# AE1C1F4051920PH0_CM55_HE_View register map
Vendor: Alif Semiconductor; Series: E1; File version: 1.0
CPU: CM55 r1p0, selectable endian, MPU, FPU, double-precision FPU, DSP, VTOR, 8 interrupt priority bits, 1 SAU regions
Registers are 32-bit, read-write, reset 0x0 unless marked. A register's access mark holds for its fields unless they carry their own. Offsets are from the block's base; [hi:lo] are bit positions; {n}, {i} and the like mark numbered series.

## LPUART
Base 0x43008000
Same registers: HCI_UART 0x4300A000, AHI_UART 0x4300B000, UART0 0x49018000, UART1 0x49019000, UART2 0x4901A000, UART3 0x4901B000, UART4 0x4901C000, UART5 0x4901D000
0x00 UART_RBR ro — Receive Buffer Register
  [8:0] RBR — Receive Buffer Register Field This field contains the data byte received on the serial input port. The data is valid only if the UART_LSR[DR] is set. If FIFOs are disabled (UART_FCR[FIFOE] set to 0), the data in the UART_RBR must be read before the next data arrives, otherwise it will be overwritten, resulting in an over-run error. If FIFOs are enabled (UART_FCR[FIFOE] set to 1), this register accesses the head of the Rx FIFO. If the Rx FIFO is full and this field is not read before the next data character arrives, then the data already in the FIFO will be preserved, but any incoming data will be lost and an over-run error occurs.
0x00 UART_DLL (alternate view of UART_RBR) — Divisor Latch Low Register
  [7:0] DLL — Divisor Latch Low Field The output baud rate is equal to serial clock frequency (SCLK for UART, PCLK for LPUART) divided by 16 times the value of the baud rate divisor, as follows: baud rate = (serial clock frequency) / (16 x divisor). Note: With the Divisor Latch registers (UART_DLL and UART_DLH) set to 0, the baud clock is disabled and no serial communication will occur. Also, once the DLL is set, at least 8 clock cycles of the slowest UART clock should be allowed to pass before transmitting or receiving data.
0x00 UART_THR (alternate view of UART_RBR) — Transmit Holding Register
  [8:0] THR wo — This field contains data to be transmitted on the serial output port. Data should only be written to the THR when the UART_LSR[THRE] is set. If FIFOs are disabled (UART_FCR[FIFOE] set to 0) and UART_LSR[THRE] is set, writing a single character to the THR field clears the UART_LSR[THRE]. Any additional writes to the THR before the UART_LSR[THRE] is set again cause the THR data to be overwritten. If FIFOs are enabled (UART_FCR[FIFOE] set to 1) and UART_LSR[THRE] is set, 32 number of characters of data may be written to the THR before the FIFO is full. Any attempt to write data when the FIFO is full results in the write data being lost. Note: The 9^th bit is applicable only when UART_LCR_EXT[TRANSMIT_MODE]=1.
0x04 UART_DLH — Divisor Latch High Register
  [7:0] DLH — Divisor Latch High The output baud rate is equal to serial clock frequency (SCLK for UART, PCLK for LPUART) divided by 16 times the value of the baud rate divisor, as follows: baud rate = (serial clock frequency) / (16 x divisor). Note: With the Divisor Latch registers (UART_DLL and UART_DLH) set to 0, the baud clock is disabled and no serial communication will occur. Also, once the DLH is set, at least 8 clock cycles of the slowest UART clock should be allowed to pass before transmitting or receiving data.
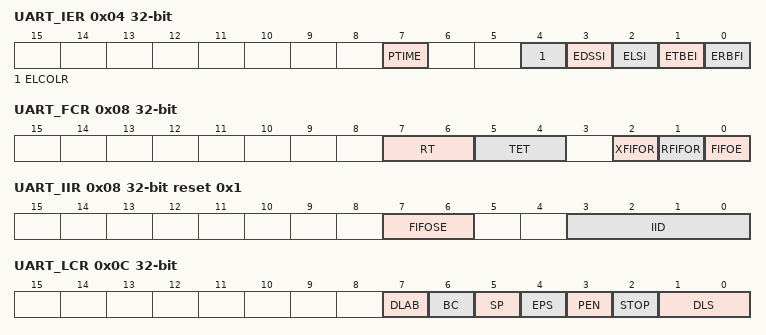
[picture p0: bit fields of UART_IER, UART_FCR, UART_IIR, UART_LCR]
0x04 UART_IER (alternate view of UART_DLH) — Interrupt Enable Register
  [7] PTIME — Programmable THRE Interrupt Mode Enable This bit is used to enable/disable the generation of THRE interrupt.
    0=Disable programmable THRE interrupt mode; 1=Enable programmable THRE interrupt mode
  [4] ELCOLR ro — This bit controls the method for clearing the status in the UART_LSR register. This is applicable only for overrun error, parity error, framing error, and break interrupt status bits of UART_LSR register.
    0=UART_LSR status bits are cleared either on reading Rx FIFO (UART_RBR) or UART_LSR register. The overrun error interrupt status is cleared only on reading UART_LSR register.
  [3] EDSSI — Enable Modem Status Interrupt This bit is used to enable/disable the generation of Modem Status interrupt. This is the fourth highest priority interrupt.
    0=Disable Modem Status interrupt; 1=Enable Modem Status interrupt
  [2] ELSI — Enable Receiver Line Status Interrupt This bit is used to enable/disable the generation of Receiver Line Status interrupt. This is the highest priority interrupt.
    0=Disable Receiver Line Status interrupt; 1=Enable Receiver Line Status interrupt
  [1] ETBEI — Enable Transmit Holding Register Empty Interrupt This bit is used to enable/disable the generation of THRE Interrupt. This is the third highest priority interrupt.
    0=Disable THRE interrupt; 1=Enable THRE interrupt
  [0] ERBFI — Enable Received Data Available Interrupt This bit is used to enable/disable the generation of Received Data Available interrupt and the Character Timeout interrupt (if FIFOs are enabled). These are the second highest priority interrupts.
    0=Disable Received Data Available interrupt; 1=Enable Received Data Available interrupt
0x08 UART_FCR — FIFO Control Register
  [7:6] RT wo — Rx Trigger This field is used to select the trigger level in the Rx FIFO at which the Received Data Available interrupt will be generated. In Auto Flow Control mode, it is used to determine when the RTS signal will be deasserted, but only when RTC flow-control trigger is disabled. It also determines when the DMA_RX_REQ signal will be asserted when in certain modes of operation. For details on DMA support, refer to Section UART DMA Requests.
    0=1 character in FIFO; 1=FIFO 1/4 full; 2=FIFO 1/2 full; 3=FIFO 2 characters till full
  [5:4] TET wo — Tx Empty Trigger This field is used to select the empty threshold level at which the THRE interrupts will be generated when the mode is active. It also determines when the DMA_TX_REQ signal will be asserted when in certain modes of operation. For details on DMA support, refer to Section UART DMA Requests.
    0=FIFO Empty; 1=2 characters in FIFO; 2=FIFO 1/4 full; 3=FIFO 1/2 full
  [2] XFIFOR wo — Tx FIFO Reset This bit resets the control portion of the Tx FIFO and treats the FIFO as empty. This will also deassert the DMA Tx request and single signals. Note that this bit is self-clearing.
    1=Tx FIFO reset
  [1] RFIFOR wo — Rx FIFO Reset This bit resets the control portion of the Rx FIFO and treats the FIFO as empty. This will also deassert the DMA Rx request and single signals. Note that this bit is self-clearing.
    1=Rx FIFO reset
  [0] FIFOE wo — FIFO Enable This bit enables/disables the Tx FIFOs and Rx FIFOs. Whenever the value of this bit is changed, both the Tx FIFO and Rx FIFO control portion of FIFOs are reset.
    0=FIFO disabled; 1=FIFO enabled
0x08 UART_IIR ro reset 0x1 (alternate view of UART_FCR) — Interrupt Identification Register
  [7:6] FIFOSE — FIFOs Enabled This field is used to indicate whether the FIFOs are enabled or disabled.
    0=FIFOs are disabled; 3=FIFOs are enabled
  [3:0] IID — Interrupt ID This field indicates the highest priority pending interrupt which can be one of the following types:
    0=Modem Status interrupt; 1=No interrupt pending; 2=THRE interrupt; 4=Received Data Available interrupt; 6=Receiver Line Status interrupt; 12=Character Timeout interrupt (can only occur when the FIFOs are enabled)
0x0C UART_LCR — Line Control Register
  [7] DLAB — Divisor Latch Access Bit This bit is used to enable reading and writing of the Divisor Latch registers (UART_DLL and UART_DLH). This bit must be cleared after initial baud rate setup in order to access other registers.
    0=Divisor Latch register is writable only when UART is not busy; 1=Divisor Latch register is always readable and writable
  [6] BC — Break Control Bit This bit is used to cause a break condition to be transmitted to the receiving device. If set to 1, the UART_TX is forced to the spacing (logic 0) state. When not in Loopback mode, as determined by UART_MCR[LOOPBACK], the UART_TX is forced low until the bit is cleared. When in Loopback mode, the break condition is internally looped back to the receiver.
    0=UART_TX is released for data transmission; 1=UART_TX is forced to spacing state
  [5] SP — Stick Parity This bit is used to force parity value. When PEN, EPS and SP bits are set to 1, the parity bit is transmitted and checked as logic 0. If PEN and SP are set to 1 and EPS is a logic 0, then parity bit is transmitted and checked as a logic 1.
    0=Stick parity disabled; 1=Stick parity enabled
  [4] EPS — Even Parity Select This bit is used to select between even and odd parity, when PEN set to 1.
    0=An odd parity is transmitted or checked; 1=An even parity is transmitted or checked
  [3] PEN — Parity Enable This bit is used to enable/disable parity generation and detection in transmitted and received serial character, respectively.
    0=Disable parity; 1=Enable parity
  [2] STOP — Number of Stop Bit This bit is used to select the number of stop bits per character that the peripheral will transmit and receive. If set to 0, one stop bit is transmitted in the serial data. If set to 1 and the data bits are set to 5 (UART_LCR[DLS] set to 0) one and a half stop bits are transmitted. Otherwise, 2 stop bits are transmitted. Note that regardless of the number of stop bits selected the receiver will only check the first stop bit. The STOP bit duration implemented by UART may appear longer due to IDLE time inserted between characters for some configurations and baud clock divisor values in the transmit direction; for details on IDLE time between transmitted transfers, refer to Section UART Back-to-Back Character Stream Transmission
    0=1 stop bit; 1=1.5 stop bits when UART_LCR[DLS] is 0, 2 stop bits otherwise
  [1:0] DLS — Data Length Select When UART_LCR_EXT[DLS_E] set to 0, this field is used to select the number of data bits per character that the peripheral will transmit and receive.
    {v}={v+5} data bits per character (v=0..3)
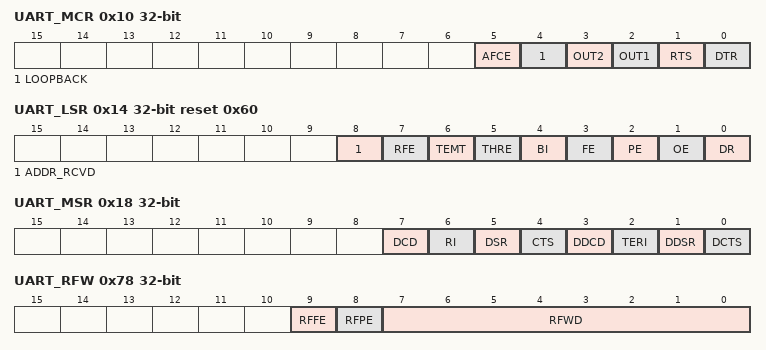
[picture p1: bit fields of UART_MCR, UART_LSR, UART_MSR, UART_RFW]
0x10 UART_MCR — Modem Control Register
  [5] AFCE — Auto Flow Control Enable When this bit is set and FIFOs are enabled, Auto Flow Control features are enabled.
    0=Auto Flow Control mode disabled; 1=Auto Flow Control mode enabled
  [4] LOOPBACK — Loopback Bit This bit is used to put the UART into a diagnostic mode for test purposes. Data on the UART_TX is held high, while UART_TX is looped back to the UART_RX, internally. In this mode all the interrupts are fully functional. In Loopback mode, the modem control inputs are disconnected and the modem control outputs are looped back to the inputs internally.
    0=Loopback mode disabled; 1=Loopback mode enabled
  [3] OUT2 — This bit is used to directly control the internal OUT2 signal. The value written to this location is inverted and driven out on OUT2. Note that in Loopback mode (UART_MCR[LOOPBACK] set to 1), the OUT2 signal is held inactive high while the value of this location is internally looped back to an input.
    0=OUT2 signal deasserted (logic 1); 1=OUT2 signal asserted (logic 0)
  [2] OUT1 — This bit is used to directly control the internal OUT1 signal. The value written to this location is inverted and driven out on OUT1. Note that in Loopback mode (UART_MCR[LOOPBACK] set to 1), the OUT1 signal is held inactive high while the value of this location is internally looped back to an input.
    0=OUT1 signal deasserted (logic 1); 1=OUT1 signal asserted (logic 0)
  [1] RTS — Request to Send This bit is used to directly control the UART_RTS output. The RTS bit is used to inform the modem that the UART is ready to exchange data. When Auto Flow Control mode is not enabled (UART_MCR[AFCE] set to 0), the UART_RTS is set low by programming UART_MCR[RTS] to high. When both Auto Flow Control mode and FIFOs are enabled (UART_MCR[AFCE] set to 1 and UART_FCR[FIFOE] set to 1, respectively), the UART_RTS is controlled in the same way, but is also gated with the Rx FIFO threshold trigger (UART_RTS is inactive high when above the threshold). The UART_RTS output will be deasserted when UART_MCR[RTS] is set to 0. Note that in Loopback mode (UART_MCR[LOOPBACK] set to 1), the UART_RTS output remains held inactive high, while the value of this bit is internally looped back to an input.
    0=UART_RTS deasserted (logic 1); 1=UART_RTS asserted (logic 0)
  [0] DTR — Data Terminal Ready This bit is used to directly control the DTR output. The value written to this bit is inverted and driven out on DTR. The DTR output is used to inform the modem that the UART is ready to establish communications. Note that in Loopback mode (UART_MCR[LOOPBACK] set to 1), the DTR output is held inactive high while the value of this bit is internally looped back to an input.
    0=DTR output deasserted (logic1); 1=DTR output asserted (logic 0)
0x14 UART_LSR ro reset 0x60 — Line Status Register
  [8] ADDR_RCVD — Address Received If 9-bit data mode is enabled (UART_LCR_EXT[DLS_E] set to 1), this bit is used to indicate the 9^th bit of the receive data is set to 1. This bit can also be used to indicate whether the incoming character is address or data. The 9^th bit, associated with a received character, is revealed when a character with the 9th bit set to 1 is at the top of the FIFO. Reading the UART_LSR clears the 9^th bit. Note: Read UART_LSR register before the next address byte arrives. If there is a delay in clearing the interrupt, then software will not be able to distinguish between multiple address related interrupts.
    0=Indicates the character is data; 1=Indicates the character is address
  [7] RFE — Rx FIFO Error This bit is only relevant when FIFOs are enabled (UART_FCR[FIFOE] set to 1). This bit is used to indicate if there is at least one parity error, framing error, or break interrupt in the FIFO. This bit is cleared when the UART_LSR is read and the character with the error is at the top of the Rx FIFO and there are no subsequent errors in the FIFO.
    0=No error in Rx FIFO; 1=Error in Rx FIFO
  [6] TEMT — Transmitter Empty If FIFOs are enabled (UART_FCR[FIFOE] set to 1), this bit is set whenever the internal transmit shift register and the Tx FIFO are both empty. If the FIFOs are disabled, this bit is set whenever the UART_THR and the transmit shift register are both empty.
    0=Transmitter not empty; 1=Transmitter empty
  [5] THRE — Transmit Holding Register Empty If THRE mode is disabled (UART_IER[PTIME] set to 0), regardless of whether FIFOs are enabled or not, this bit indicates that the UART_THR or Tx FIFO is empty. This bit is set whenever data is transferred from the UART_THR or Tx FIFO to the transmit shift register, and no new data has been written to the UART_THR or Tx FIFO. This also causes a THRE interrupt to occur, if the THRE interrupt is enabled. If both THRE Interrupt mode (UART_IER[PTIME] set to 1) and FIFOs (UART_FCR[FIFOE] set to 1) are enabled, the functionality is switched to indicate the Tx FIFO is full, and no longer controls THRE interrupts, which are then controlled by the UART_FCR[TET] threshold setting.
    0=THRE interrupt control is disabled; 1=THRE interrupt control is enabled
  [4] BI — Break Interrupt This bit is used to indicate the detection of a break sequence on the serial input data. This bit is set whenever the UART_RX is held in a logic 0 state for longer than the sum of start time + data bits + parity + stop bits. If the FIFOs are enabled, the character associated with the break condition is carried through the FIFO and is revealed when the character is at the top of the FIFO. Reading the UART_LSR or UART_RBR clears the BI bit. If FIFOs are disabled, this bit is set immediately and persists until the UART_LSR is read. Note: If a FIFO is full when a break condition is received, a FIFO overrun occurs. The break condition and all the information associated with it-parity and framing errors-is discarded; any information that a break character was received is lost.
    0=No break sequence detected; 1=Break sequence detected
  [3] FE — Framing Error This bit is used to indicate the occurrence of a framing error in the receiver. A framing error occurs when the receiver does not detect a valid STOP bit in the received data (see UART_LCR[STOP]). If the FIFOs are enabled, the framing error is associated with a character received, it is revealed when the character with the framing error is at the top of the FIFO. When a framing error occurs, the UART will attempt to resynchronize. It does this by assuming that the error was due to the start bit of the next character and then continues receiving the other bit (data, and/or parity, and stop). It should be noted that the UART_LSR[FE] bit will be set if a break interrupt has occurred, as indicated by the BI bit. This happens because the break character implicitly generates a framing error by holding the UART_RX to logic 0 for longer than the duration of a character. Reading the UART_LSR or UART_RBR clears this bit.
    0=No framing error; 1=Framing error
  [2] PE — Parity Error This bit is used to indicate the occurrence of a parity error in the receiver if the UART_LCR[PEN] bit is set. If the FIFOs are enabled, the parity error is associated with a character received, it is revealed when the character with the parity error arrives at the top of the FIFO. It should be noted that this bit will be set if a break interrupt has occurred, as indicated by the BI bit. In this situation, the PE bit is set if parity generation and detection is enabled (UART_LCR[PEN] is set to 1) and the parity is set to odd (UART_LCR[EPS] is set to 0). Reading the UART_LSR or UART_RBR clears this bit.
    0=No parity error; 1=Parity error
  [1] OE — Overrun Error This bit is used to indicate the occurrence of an overrun error. This occurs if a new data character was received before the previous data was read. If the FIFOs are enabled, an overrun error occurs when the FIFO is full and a new character arrives at the receiver. The data in the FIFO is retained and the data in the receive shift register is lost. Reading the UART_LSR or UART_RBR clears this bit.
    0=No overrun error; 1=Overrun error
  [0] DR — Data Ready This bit is used to indicate that the receiver contains at least one character in the UART_RBR or the receiver FIFO. This bit is cleared when the UART_RBR is read (if FIFOs are disabled) or when the receiver FIFO is empty (if FIFOs are enabled).
    0=No data ready; 1=Data ready
0x18 UART_MSR ro — Modem Status Register
  [7] DCD — Data Carrier Detect This bit is used to indicate the current state of the modem control line DCD. When the Data Carrier Detect input (DCD) is asserted, it indicates that the carrier has been detected by the modem or data set. In Loopback mode (UART_MCR[LOOPBACK] set to 1), DCD is the same as UART_MCR[OUT2] bit.
    0=DCD input is deasserted (logic 1); 1=DCD input is asserted (logic 0)
  [6] RI — Ring Indicator This bit is used to indicate the current state of the modem control line RI. When this bit is asserted, it indicates that a telephone ringing signal has been received by the modem data set. In Loopback mode (UART_MCR[LOOPBACK] set to 1), RI is the same as UART_MCR[OUT1].
    0=RI input is deasserted (logic 1); 1=RI input is asserted (logic 0)
  [5] DSR — Data Set Ready This bit is used to indicate the current state of the modem control line DSR. When this bit is asserted, it indicates that the modem or data set is ready to establish communications with the UART. In Loopback mode (UART_MCR[LOOPBACK] set to 1), DSR is the same as UART_MCR[DTR].
    0=DSR input is deasserted (logic 1); 1=DSR input is asserted (logic 0)
  [4] CTS — Clear to Send This bit is used to indicate the current state of the modem control line CTS. When this bit is asserted, it indicates that the modem or data set is ready to exchange data with the UART. In Loopback mode (UART_MCR[LOOPBACK] set to 1), CTS is the same as UART_MCR[RTS].
    0=CTS input is deasserted (logic 1); 1=CTS input is asserted (logic 0)
  [3] DDCD — Delta Data Carrier Detect This bit is used to indicate that the modem control line DCD has changed since the last time the UART_MSR was read. Reading the UART_MSR clears the DDCD bit. In Loopback mode (UART_MCR[LOOPBACK] set to 1), DDCD reflects changes on UART_MCR[OUT2]. Note: If the DDCD bit is not set and the DCD signal is asserted (low) and a reset occurs, then the DDCD bit will get set when the reset is removed, provided that the DCD signal remains asserted.
    0=No change on DCD since last read of UART_MSR; 1=Change on DCD since last read of UART_MSR
  [2] TERI — Trailing Edge of Ring Indicator This bit is used to indicate that a change on the input RI (from an active low, to an inactive high state) has occurred since the last time the UART_MSR was read. Reading the UART_MSR clears the TERI bit. In Loopback mode (UART_MCR[LOOPBACK] set to 1), this bit reflects a change in state from high to low for UART_MCR[OUT1].
    0=No change on RI since last read of UART_MSR; 1=Change on RI since last read of UART_MSR
  [1] DDSR — Delta Data Set Ready This bit is used to indicate that the modem control line DSR has changed since the last time the UART_MSR was read. Reading the UART_MSR clears the DDSR bit. In Loopback mode (UART_MCR[LOOPBACK] set to 1), DDSR reflects changes on UART_MCR[DTR]. Note: If the DDSR bit is not set and the DSR signal is asserted (low) and a reset occurs, then the DDSR bit will be set when the reset is removed if the DSR signal remains asserted.
    0=No change on DSR since last read of UART_MSR; 1=Change on DSR since last read of UART_MSR
  [0] DCTS — Delta Clear to Send This bit is used to indicate that the modem control line CTS has changed since the last time the UART_MSR was read. Reading the UART_MSR clears the DCTS bit. In Loopback mode (UART_MCR[LOOPBACK] set to 1), DCTS reflects changes on UART_MCR[RTS]. Note: If the DCTS bit is not set and the CTS signal is asserted (low) and a reset occurs, then the DCTS bit will be set when the reset is removed if the CTS signal remains asserted.
    0=No change on CTS since last read of UART_MSR; 1=Change on CTS since last read of UART_MSR
0x1C UART_SCR — Scratchpad Register
  [7:0] SCR — This field is used as a temporary storage space. It has no defined purpose in the UART.
{0x30+4i} UART_SRBR[{i}] (i=0..15) ro — Shadow Receive Buffer Register (n)
  [8:0] SRBRN — This is a shadow field for the UART_RBR[RBR] field and has been allocated sixteen 32-bit locations to accommodate burst accesses from the master. This field contains the data byte received on the UART_RX. The data in this field is valid only if the UART_LSR[DR] bit is set. If FIFOs are disabled (UART_FCR[FIFOE] set to 0), the data in the UART_RBR[RBR] must be read before the next data arrives, otherwise it will be overwritten, resulting in an overrun error. If FIFOs are enabled (UART_FCR[FIFOE] set to 1), this register accesses the head of the Rx FIFO. If the Rx FIFO is full and this field is not read before the next data character arrives, then the data already in the FIFO will be preserved, but any incoming data will be lost. An overrun error will also occur.
{0x30+4i} UART_STHR[{i}] (i=0..15) (alternate view of UART_SRBR[{i}]) — Shadow Transmit Holding Register (n)
  [8:0] STHRN wo — This is a shadow field for the UART_THR[THR] and has been allocated sixteen 32-bit locations to accommodate burst accesses from the master. This field contains data to be transmitted on the UART_TX. Data should only be written to the UART_THR when the UART_LSR[THRE] bit is set. If FIFOs are disabled (UART_FCR[FIFOE] set to 0) and UART_LSR[THRE] is set, writing a single character to the UART_THR[THR] clears the UART_LSR[THRE]. Any additional writes to the UART_THR[THR] before the UART_LSR[THRE] is set again causes the UART_THR[THR] data to be overwritten. If FIFOs are enabled (UART_FCR[FIFOE] set to 1) and UART_LSR[THRE] is set, 32 data characters may be written to the UART_THR[THR] before the FIFO is full. Any attempt to write data when the FIFO is full results in the write data being lost.
0x70 UART_FAR — FIFO Access Register
  [0] FAR — This bit is used to enable a FIFO access mode for testing, so that the Rx FIFO can be written and the Tx FIFO can be read by the master when FIFOs are enabled. When FIFOs are not enabled, it allows the UART_RBR[RBR] to be written by the master and the UART_THR[THR] to be read by the master. Note: When the FIFO access mode is enabled/disabled, the control portion of the Rx FIFO and Tx FIFO is reset and the FIFOs are treated as empty.
    0=FIFO access mode disabled; 1=FIFO access mode enabled
0x74 UART_TFR ro — Tx FIFO Read Register
  [7:0] TFR — This field is only valid when FIFO access mode is enabled (UART_FAR[FAR] set to 1). When FIFOs are enabled, reading this field gives the data at the top of the Tx FIFO. Each consecutive read pops the Tx FIFO and gives the next data value that is currently at the top of the FIFO. When FIFOs are not enabled, reading this field gives the data in the UART_THR[THR] field.
0x78 UART_RFW — Rx FIFO Write Register
  [9] RFFE wo — Rx FIFO Framing Error When FIFOs are enabled, this bit is used to write framing error detection information to the Rx FIFO. When FIFOs are not enabled, this bit is used to write framing error detection information to the UART_RBR[RBR].
    0=Frame error disabled; 1=Frame error enabled
  [8] RFPE wo — Rx FIFO Parity Error When FIFOs are enabled, this bit is used to write parity error detection information to the Rx FIFO. When FIFOs are not enabled, this bit is used to write parity error detection information to the UART_RBR[RBR].
    0=Parity error disabled; 1=Parity error enabled
  [7:0] RFWD wo — Rx FIFO Write Data When FIFOs are enabled, the data that is written to this field is pushed into the Rx FIFO. Each consecutive write pushes the new data to the next write location in the Rx FIFO. When FIFOs are not enabled, the data that is written to this field is pushed into the UART_RBR[RBR].
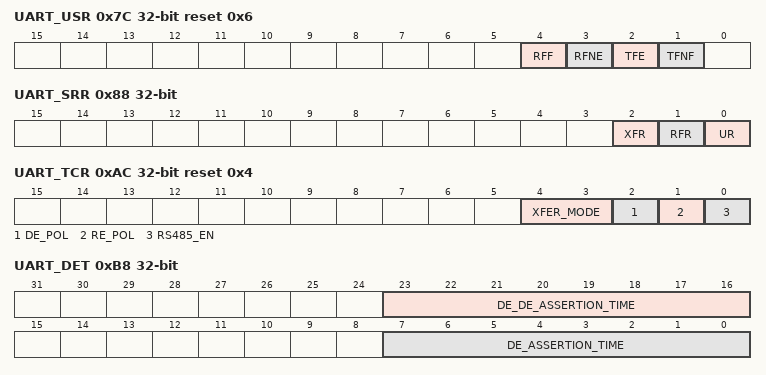
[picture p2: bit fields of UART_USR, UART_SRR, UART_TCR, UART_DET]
0x7C UART_USR ro reset 0x6 — UART Status Register
  [4] RFF — Rx FIFO Full This bit is used to indicate that the Rx FIFO is completely full. This bit is cleared when the Rx FIFO is no longer full.
    0=Rx FIFO is not full; 1=Rx FIFO is full
  [3] RFNE — Rx FIFO Not Empty This bit is used to indicate that the Rx FIFO contains one or more entries. This bit is cleared when the Rx FIFO is empty.
    0=Rx FIFO is empty; 1=Rx FIFO is not empty
  [2] TFE — Tx FIFO Empty This bit is used to indicate that the Tx FIFO is completely empty. This bit is cleared when the Tx FIFO is no longer empty.
    0=Tx FIFO is not empty; 1=Tx FIFO is empty
  [1] TFNF — Tx FIFO Not Full This bit is used to indicate that the Tx FIFO is not full. This bit is cleared when the Tx FIFO is full.
    0=Tx FIFO is full; 1=Tx FIFO is not full
0x80 UART_TFL ro — Tx FIFO Level Register
  [5:0] TFL — Transmit FIFO Level This field indicates the number of data entries in the Tx FIFO.
0x84 UART_RFL ro — Rx FIFO Level Register
  [5:0] RFL — Receive FIFO Level This field indicates the number of data entries in the Rx FIFO.
0x88 UART_SRR — Software Reset Register
  [2] XFR wo — Tx FIFO Reset This is a shadow bit for the UART_FCR[XFIFOR] bit. It is used to remove the burden on software of having to store previously written UART_FCR values just to reset the Tx FIFO. This resets the control portion of the Tx FIFO and treats the FIFO as empty. This will also deassert the DMA Tx request and single signals. Note that this bit is self-clearing.
  [1] RFR wo — Rx FIFO Reset This is a shadow bit for the UART_FCR[RFIFOR] bit. It is used to remove the burden on software of having to store previously written UART_FCR values just to reset the Rx FIFO. This resets the control portion of the Rx FIFO and treats the FIFO as empty. This will also deassert the DMA Rx request and single signals. Note that this bit is self-clearing.
  [0] UR wo — UART Reset This bit asynchronously resets the UART and synchronously removes the reset assertion. Both PCLK and SCLK (UART only) will be reset.
    0=No UART reset; 1=UART reset
0x8C UART_SRTS — Shadow Request to Send Register
  [0] SRTS — This is a shadow bit for the UART_MCR[RTS] bit, used to remove the burden of having to perform a read / modify write on the UART_MCR. This is used to directly control the UART_RTS output. The UART_RTS is used to inform the modem or data set that the UART is ready to exchange data. When UART_MCR[AFCE] bit is set to 0, the UART_RTS output is set low by programming UART_MCR[RTS] to a high. When UART_MCR[AFCE] bit is set to 1 and UART_FCR[FIFOE] set to 1, the UART_RTS signal is controlled in the same way, but is also gated with the Rx FIFO threshold trigger (UART_RTS signal is in active high when above the threshold) only when RTC flow-control trigger is disabled; otherwise it is gated by the Rx FIFO almost-full trigger, where almost full refers to two available slots in the FIFO (UART_RTS signal is in active high when above the threshold). Note: In Loopback mode (UART_MCR[LOOPBACK] bit set to 1), the UART_RTS signal is held in active high while the value of this bit is internally looped back to an input.
    0=Shadow UART_RTS logic 1; 1=Shadow UART_RTS logic 0
0x90 UART_SBCR — Shadow Break Control Register
  [0] SBCB — This is a shadow bit for the UART_LCR[BC] bit, used to remove the burden of having to perform a read / modify write on the UART_LCR. It is used to cause a break condition to be transmitted to the receiving device. If SBCB is set to 1 the UART_TX signal is forced to the spacing (logic 0) state. When not in Loopback mode (UART_MCR[LOOPBACK] set to 0), the UART_TX signal is forced low until the UART_LCR[BC] bit is cleared.
    0=No spacing on UART_TX signal; 1=UART_TX forced to the spacing
0x98 UART_SFE — Shadow FIFO Enable Register
  [0] SFE — This is a shadow bit for the UART_FCR[FIFOE] bit. It is used to remove the burden of having to store the previously written value to the UART_FCR in memory and and masking it, so that only the UART_FCR[FIFOE] bit gets updated. This enables/disables the Tx and Rx FIFOs. If this bit is set to 0 after being enabled then both the Tx and Rx control portion of FIFOs will be reset.
    0=FIFOs are disabled; 1=FIFOs are enabled
0x9C UART_SRT — Shadow RCVR Trigger Register
  [1:0] SRT — This is a shadow field for the UART_FCR[RT] field. It is used to remove the burden of having to store the previously written value to the UART_FCR[RT] in memory and and masking it, so that only the UART_FCR[RT] bit gets updated. SRT is used to select the trigger level in the Rx FIFO at which the Received Data Available interrupt will be generated.
    0=1 character in FIFO; 1=FIFO 1/4 full; 2=FIFO 1/2 full; 3=FIFO 2 less than full
0xA0 UART_STET — Shadow Tx Empty Trigger Register
  [1:0] STET — This is a shadow field for the UART_FCR[TET] field. It is used to remove the burden of having to store the previously written value to the UART_FCR[TET] in memory and and masking it, so that only the UART_FCR[TET] bit gets updated. STET is used to select the empty threshold level at which the THRE interrupts will be generated when the mode is active.
    0=FIFO empty; 1=2 characters in FIFO; 2=FIFO 1/4 full; 3=FIFO 1/2 full
0xA4 UART_HTX — Halt Tx Register
  [0] HTX — This bit is used to halt transmissions for testing, so that the Tx FIFO is filled by the master when FIFOs are enabled. Note: If FIFOs are not enabled the setting of this bit will have no effect on operation.
    0=Halt transmission disabled; 1=Halt transmission enabled
0xA8 UART_DMASA — DMA Software Acknowledge Register
  [0] DMASA wo — This bit is used to perform DMA software acknowledge if a transfer needs to be terminated due to an error condition. For example, if the DMA disables the channel, then the UART should clear its request. This will cause the Tx request, Tx single, Rx request and Rx single signals to deassert. Note: This bit is self-clearing.
    1=DMA software acknowledge
0xAC UART_TCR reset 0x4 — Transceiver Control Register
  [4:3] XFER_MODE — Transfer Mode Hardware will consider the Turnaround timings programmed in the UART_TAT register while switching from RE to DE, or DE to RE. For transmission hardware will wait if it is in middle of receiving any transfer, before it starts transmitting. Once the Tx FIFO becomes empty, RE signal gets enabled and DE signal will be disabled. Hardware will consider the Turnaround timings which are programmed in the UART_TAT register while switching from RE to DE or DE to RE. The DE and RE signals are strictly complementary to each other.
    0=In this mode, transmit and receive can happen simultaneously. UART_DE_EN[DE_ENABLE], UART_RE_EN[RE_ENABLE] can be enabled at any point of time. Turnaround timing as programmed in the UART_TAT register is not applicable in this mode.; 1=In this mode, DE and RE are mutually exclusive. Either DE or RE is expected to be enabled.; 2=In this mode, DE and RE are mutually exclusive. Once UART_DE_EN/UART_RE_EN register is set-by default RE will be enabled and UART controller will be ready to receive. If the SW programs the Tx FIFO with the data, then UART (after ensuring no receive is in progress), disables RE and enables DE signal.
  [2] DE_POL — Driver Enable Polarity
    0=DE signal is active low; 1=DE signal is active high
  [1] RE_POL — Receiver Enable Polarity NOTE: The reset value for UART is 0x0, and for LPUART it is 0x1.
    0=RE signal is active low; 1=RE signal is active high
  [0] RS485_EN — RS485 Transfer Enable
    1=The transfers will happen in RS485 mode. All other fields of this register are applicable.
0xB0 UART_DE_EN — Driver Output Enable Register
  [0] DE_ENABLE — This bit is used to control assertion and deassertion of DE signal.
    0=Deassert DE signal; 1=Assert DE signal
0xB4 UART_RE_EN — Receiver Output Enable Register
  [0] RE_ENABLE — This bit is used to control assertion and deassertion of RE signal.
    0=Deassert RE signal; 1=Assert RE signal
0xB8 UART_DET — Driver Output Enable Timing Register
  [23:16] DE_DE_ASSERTION_TIME — Driver Enable Deassertion Time This field controls the amount of time (in terms of number of SCLK periods) between the end of the stop bit on the UART_TX signal to the falling edge of DE signal.
  [7:0] DE_ASSERTION_TIME — Driver Enable Assertion Time This field controls the amount of time (in terms of number of SCLK periods) between the assertion of rising edge of DE signal to serial transmit enable. Any data in transmit buffer, will start on UART_TX signal after the transmit enable.
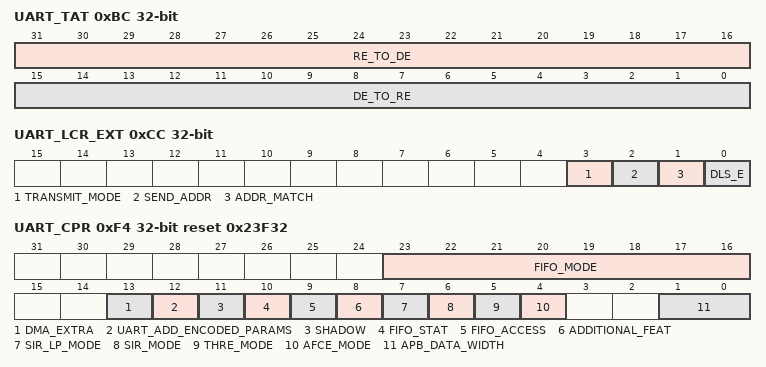
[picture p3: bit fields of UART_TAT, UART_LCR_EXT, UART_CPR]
0xBC UART_TAT — Turnaround Timing Register
  [31:16] RE_TO_DE — Receiver Enable to Driver Enable Turnaround time Turnaround time (in terms of SCLK) for RE deassertion to DE assertion: - If the UART_DET[DE_ASSERTION_TIME] field is 0, then the actual value is the programmed value + 3. - If the UART_DET[DE_ASSERTION_TIME] field is 1, then the actual value is the programmed value + 2. - If the UART_DET[DE_ASSERTION_TIME] field is greater than 1, then the actual value is the programmed value + 1.
  [15:0] DE_TO_RE — Driver Enable to Receiver Enable TurnAround time. Turnaround time (in terms of SCLK) for DE Deassertion to RE assertion: The actual time is the programmed value + 1.
0xC0 UART_DLF — Divisor Latch Fraction Register
  [3:0] DLF — This field defines the fractional value that is added to the integer value set by UART_DLH, UART_DLL. Fractional value = DLF / 2^DLF_SIZE, where DLF_SIZE = 4. For more information, see Section UART Fractional Baud Rate Support.
0xC4 UART_RAR — Receive Address Register
  [7:0] RAR — This field is an address matching field during Receive mode. If the 9^th bit is set in the incoming character, then the remaining 8-bits will be checked against this field value. If the match happens, then sub-sequent characters with 9^th bit set to 0 will be treated as data byte until the next address byte is received. This field is applicable only when UART_LCR_EXT[ADDR_MATCH] and UART_LCR_EXT[DLS_E] bits are set to 1. RAR can be programmed at any point of the time. However, it must not be changed during any receive is in progress.
0xC8 UART_TAR — Transmit Address Register
  [7:0] TAR — This field is an address matching field during Transmit mode. If UART_LCR_EXT[DLS_E] bit is enabled, then UART will send the 9-bit character with 9^th bit set to 1, and remaining 8-bit address will be sent from this field, provided UART_LCR_EXT[SEND_ADDR] bit set to 1. This field is used only to send the address. The normal data should be sent by programming UART_THR[THR] field. Once the address starts to be send on the UART serial lane, then UART_LCR_EXT[SEND_ADDR] bit will be auto-cleared.
0xCC UART_LCR_EXT — Line Extended Control Register
  [3] TRANSMIT_MODE — Transmit Mode Control This bit is used to control the type of Transmit mode during 9-bit data transfers. Ensure that the UART_THR/UART_STHRn registers are written correctly for address/data: - Address: 9^th bit set to 1 - Data: 9^th bit set to 0 Note: In this mode of operation: - UART_TAR[TAR] field is not applicable - UART_DLH and UART_DLL are always readable and writable
    0=In this mode of operation, UART_THR[THR] field and fields of UART_STHRn registers are 8-bitwide. Program the address into UART_TAR[TAR] field and data intothe UART_THR/UART_STHRn registers. The UART_LCR_EXT[SEND_ADDR] bit is used as a control knob to indicate the UART when to send the address.; 1=In this mode of operation, UART_THR[THR] field and fields of UART_STHRn registers are 9-bitwide
  [2] SEND_ADDR — Send Address Control This bit is used as a control knob to determine when to send the address during Transmit mode. This bit is auto-cleared after sending out the address character. This field is applicable only when UART_LCR_EXT[DLS_E] bit is set to 1 and UART_LCR_EXT[TRANSMIT_MODE] is set to 0.
    0=9-bit character will be transmitted with 9^th bit set to 0 and the remaining 8-bits will be taken from the Tx FIFO which is programmed through 8-bit wide UART_THR/UART_STHRn registers; 1=9-bit character will be transmitted with 9^th bit set to 1 and the remaining 8-bits will match to what is being programmed in UART_TAR register
  [1] ADDR_MATCH — Address Match Mode This bit is used to enable the address match feature during Receive mode. This bit is applicable only when UART_LCR_EXT[DLS_E] is set to 1.
    0=Normal mode. The UART will start to receive the data and 9-bit character will be formed and written into the receive Rx FIFO. User is responsible to read the data and differentiate address and data.; 1=Address match mode. The UART will wait until the incoming character with 9^th bit set to 1 and then checks if the address matches the one programmed in the UART_RAR register. If match is found, then sub-sequent characters will be treated as valid data and UART starts receiving data.
  [0] DLS_E — Extension for DLS This bit is used to enable 9-bit data for transmit and receive transfers.
0xD4 UART_REG_TIMEOUT_RST reset 0x8 — Timeout Counter Reset Value Register
  [3:0] REG_TIMEOUT_RST — This field holds reset value of the register timeout counter.
0xF4 UART_CPR ro reset 0x23F32 — Module Configuration Register
  [23:16] FIFO_MODE — The value of this field defines the FIFO mode.
    2=FIFO depth is 32
  [13] DMA_EXTRA — The value of this bit defines the DMA interface.
    1=DMA interface enabled
  [12] UART_ADD_ENCODED_PARAMS — The value of this bit determines whether encoded information about module configuration settings can be read.
    1=The encoded information can be read
  [11] SHADOW — The value of this bit determines the availability of shadow registers.
    1=Shadow registers are available
  [10] FIFO_STAT — The value of this bit defines the availability of FIFO status registers
    1=FIFO status registers are available
  [9] FIFO_ACCESS — The value of this bit determines whether the UART has programmable FIFO access mode. NOTE: The reset value for UART is 0x1, and for LPUART it is 0x0.
    1=FIFO ACCESS enabled (UART only); 0=FIFO ACCESS disabled (LPUART only)
  [8] ADDITIONAL_FEAT — The value of this bit defines the additional features.
    1=Additional features enabled
  [7] SIR_LP_MODE — The value of this bit defines the SIR low power mode.
    0=SIR_LP mode disabled
  [6] SIR_MODE — The value of this bit defines the SIR mode.
    0=SIR mode disabled
  [5] THRE_MODE — The value of this bit defines the THRE mode.
    1=THRE mode enabled
  [4] AFCE_MODE — The value of this bit defines the AFCE mode.
    1=AFCE mode enabled
  [1:0] APB_DATA_WIDTH — The value of this field defines the APB data width.
    2=APB data width is 32 bits
0xF8 UART_UCV ro reset 0x3430322A — Component Version Register
  [31:0] UART_COMPONENT_VERSION — Component version NOTE: The reset value for UART is 0x3430322A, and for LPUART it is 0x3430332A.
0xFC UART_CTR ro reset 0x44570110 — Component Type Register
  [31:0] PERIPHERAL_ID — Component type
